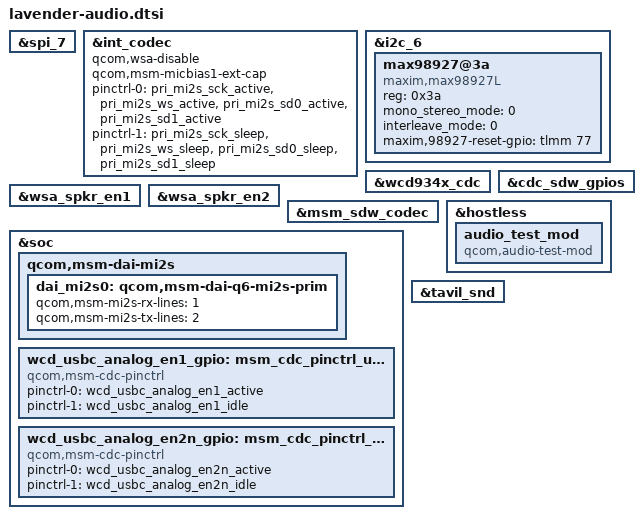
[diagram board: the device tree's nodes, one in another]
&spi_7 {
	status = "okay";
};

&int_codec {
	qcom,wsa-disable;
};

&i2c_6 { /* SmartPA TI */
	status = "okay";
	max98927@3a {
		compatible = "maxim,max98927L";
		status = "okay";
		reg = <0x3a>;
		mono_stereo_mode = <0>;
		interleave_mode = <0>;
		maxim,98927-reset-gpio = <&tlmm 77 0>;
	};
};

/* sdm660-audio.dtsi diff */
&wcd934x_cdc {
	/delete-node/ msm_cdc_pinctrl_usbc_audio_en1;
	/delete-node/ msm_cdc_pinctrl_usbc_audio_en2;
};

&cdc_sdw_gpios {
	/delete-property/ pinctrl-names;
	/delete-property/ pinctrl-0;
	/delete-property/ pinctrl-1;
};

&wsa_spkr_en1 {
	/delete-property/ pinctrl-names;
	/delete-property/ pinctrl-0;
	/delete-property/ pinctrl-1;
};

&wsa_spkr_en2 {
	/delete-property/ pinctrl-names;
	/delete-property/ pinctrl-0;
	/delete-property/ pinctrl-1;
};

&msm_sdw_codec {
	/delete-property/ qcom,cdc-sdw-gpios;
};

/* msm-audio.dtsi diff */
&soc {
	qcom,msm-dai-mi2s {
		dai_mi2s0: qcom,msm-dai-q6-mi2s-prim {
			qcom,msm-mi2s-rx-lines = <1>;
			qcom,msm-mi2s-tx-lines = <2>;
		};
	};
};

&hostless {
	audio_test_mod {
		compatible = "qcom,audio-test-mod";
	};
};

&tavil_snd {
	/delete-property/qcom,usbc-analog-en1_gpio;
	/delete-property/qcom,usbc-analog-en2_n_gpio;
};

&int_codec {
	qcom,wsa-disable;
	qcom,msm-micbias1-ext-cap;
	/delete-property/ qcom,msm-micbias2-ext-cap;
	/delete-property/ qcom,us-euro-gpios;
	pinctrl-names = "pri_i2s_active", "pri_i2s_sleep";
	pinctrl-0 = <&pri_mi2s_sck_active &pri_mi2s_ws_active 
			&pri_mi2s_sd0_active &pri_mi2s_sd1_active>;
	pinctrl-1 = <&pri_mi2s_sck_sleep &pri_mi2s_ws_sleep 
			&pri_mi2s_sd0_sleep &pri_mi2s_sd1_sleep>;
};

&soc {
	wcd_usbc_analog_en1_gpio: msm_cdc_pinctrl_usbc_audio_en1 {
		compatible = "qcom,msm-cdc-pinctrl";
		pinctrl-names = "aud_active", "aud_sleep";
		pinctrl-0 = <&wcd_usbc_analog_en1_active>;
		pinctrl-1 = <&wcd_usbc_analog_en1_idle>;
	};

	wcd_usbc_analog_en2n_gpio: msm_cdc_pinctrl_usbc_audio_en2 {
		compatible = "qcom,msm-cdc-pinctrl";
		pinctrl-names = "aud_active", "aud_sleep";
		pinctrl-0 = <&wcd_usbc_analog_en2n_active>;
		pinctrl-1 = <&wcd_usbc_analog_en2n_idle>;
	};
};

